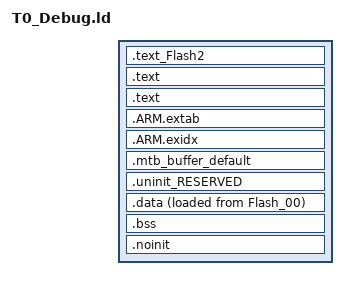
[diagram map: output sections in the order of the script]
/*
 * GENERATED FILE - DO NOT EDIT
 * (c) Code Red Technologies Ltd, 2008-13
 * (c) NXP Semiconductors 2013-2016
 * Generated linker script file for LPC824
 * Created from generic_c.ld (7.7.2 ())
 * By LPCXpresso v7.7.2 [Build 379] [2015-03-31]  on Wed Jan 20 13:37:03 EET 2016
 */


INCLUDE "T0_Debug_lib.ld"
INCLUDE "T0_Debug_mem.ld"

ENTRY(ResetISR)

SECTIONS
{
    
    .text_Flash2 : ALIGN(4)
    {
       FILL(0xff)
    	*(.text_Flash2*) /* for compatibility with previous releases */
    	*(.text_MFlash32*) /* for compatibility with previous releases */
    	*(.text.$Flash2*)
    	*(.text.$MFlash32*)
    	*(.rodata.$Flash2*)
    	*(.rodata.$MFlash32*)
    } > MFlash32

    /* MAIN TEXT SECTION */    
    .text : ALIGN(4)
    {
        FILL(0xff)
        __vectors_start__ = ABSOLUTE(.) ;
        KEEP(*(.isr_vector))
        
        /* Global Section Table */
        . = ALIGN(4) ;
        __section_table_start = .;
        __data_section_table = .;
        LONG(LOADADDR(.data));
        LONG(    ADDR(.data));
        LONG(  SIZEOF(.data));
        __data_section_table_end = .;
        __bss_section_table = .;
        LONG(    ADDR(.bss));
        LONG(  SIZEOF(.bss));
        __bss_section_table_end = .;
        __section_table_end = . ;
        /* End of Global Section Table */
        

        *(.after_vectors*)
        
    } >Flash_00
    
    .text : ALIGN(4)    
    {
         *(.text*)
        *(.rodata .rodata.* .constdata .constdata.*)
        . = ALIGN(4);
        
    } > Flash_00

    /*
     * for exception handling/unwind - some Newlib functions (in common
     * with C++ and STDC++) use this. 
     */
    .ARM.extab : ALIGN(4)
    {
    	*(.ARM.extab* .gnu.linkonce.armextab.*)
    } > Flash_00
    __exidx_start = .;
    
    .ARM.exidx : ALIGN(4)
    {
    	*(.ARM.exidx* .gnu.linkonce.armexidx.*)
    } > Flash_00
    __exidx_end = .;
    
    _etext = .;
        
    
    /* MAIN DATA SECTION */
    
    /* Default MTB section */
    .mtb_buffer_default (NOLOAD) :
    {
       KEEP(*(.mtb*))
    } > RamLoc8 

    .uninit_RESERVED : ALIGN(4)
    {
        KEEP(*(.bss.$RESERVED*))
        . = ALIGN(4) ;
        _end_uninit_RESERVED = .;
    } > RamLoc8

	
	/* Main DATA section (RamLoc8) */
	.data : ALIGN(4)
	{
	   FILL(0xff)
	   _data = . ;
	   *(vtable)
	   *(.ramfunc*)
	   *(.data*)
	   . = ALIGN(4) ;
	   _edata = . ;
	} > RamLoc8 AT>Flash_00


    /* MAIN BSS SECTION */
    .bss : ALIGN(4)
    {
        _bss = .;
        *(.bss*)
        *(COMMON)
        . = ALIGN(4) ;
        _ebss = .;
        PROVIDE(end = .);
    } > RamLoc8
        
    
    /* DEFAULT NOINIT SECTION */
    .noinit (NOLOAD): ALIGN(4)
    {
        _noinit = .;
        *(.noinit*) 
         . = ALIGN(4) ;
        _end_noinit = .;
    } > RamLoc8
    
    PROVIDE(_pvHeapStart = DEFINED(__user_heap_base) ? __user_heap_base : .);
    PROVIDE(_vStackTop = DEFINED(__user_stack_top) ? __user_stack_top : __top_RamLoc8 - 0);
}
